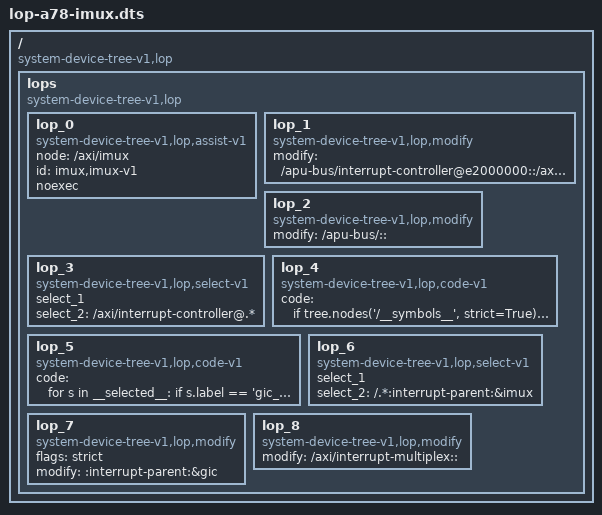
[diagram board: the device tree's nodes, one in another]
/*
 * Copyright (c) 2023 - 2024 Advanced Micro Devices, Inc. All rights reserved.
 *
 * Author:
 *       Onkar Harsh <onkar.harsh@amd.com>
 *
 * SPDX-License-Identifier: BSD-3-Clause
 */

/dts-v1/;

/ {
        compatible = "system-device-tree-v1,lop";
        lops {
                compatible = "system-device-tree-v1,lop";
                lop_0 {
                        compatible = "system-device-tree-v1,lop,assist-v1";
                        node = "/axi/imux";
                        id = "imux,imux-v1";
                        noexec;
                };

                lop_1 {
                        compatible = "system-device-tree-v1,lop,modify";
                        // Rename the interrupt controller node
                        modify = "/apu-bus/interrupt-controller@e2000000::/axi/interrupt-controller@e2000000";
                };

                lop_2 {
                        compatible = "system-device-tree-v1,lop,modify";
                        // Rename the interrupt controller node
                        modify = "/apu-bus/::";
                };

                lop_3 {
                        compatible = "system-device-tree-v1,lop,select-v1";
                        // clear any old selections
                        select_1;
                        select_2 = "/axi/interrupt-controller@.*";
                };

                lop_4 {
                      compatible = "system-device-tree-v1,lop,code-v1";
                      code = "
                                if tree.nodes('/__symbols__', strict=True):
                                        tree['/__symbols__']['gic'] = str(tree.deref('gic_a78'))
                                        tree['/__symbols__'].delete('gic_a78')
                            ";
                };

                lop_5 {
                      compatible = "system-device-tree-v1,lop,code-v1";
                      code = "
                                for s in __selected__:
                                    if s.label == 'gic_a78':
                                        s.label = 'gic'
                                        break
                            ";
                };

                lop_6 {
                      compatible = "system-device-tree-v1,lop,select-v1";
                      // clear any old selections
                      select_1;
                      select_2 = "/.*:interrupt-parent:&imux";
                };

                lop_7 {
                      compatible = "system-device-tree-v1,lop,modify";
                      // this will use the selected nodes above, to add a property
                      flags = "strict";
                      modify = ":interrupt-parent:&gic";
                };

                lop_8 {
                        compatible = "system-device-tree-v1,lop,modify";
                        // delete the interrupt-multiplex
                        modify = "/axi/interrupt-multiplex::";
                };
        };
};
